# apollo4l register map
Vendor: Ambiq Micro; Series: Apollo; File version: 1.0
CPU: CM4 r1p0, little endian, MPU, FPU, I-cache, D-cache, VTOR, ITCM, DTCM, 3 interrupt priority bits, 0 interrupts
Registers are 32-bit, read-write, reset 0x0 unless marked. A register's access mark holds for its fields unless they carry their own. Offsets are from the block's base; [hi:lo] are bit positions; {n}, {i} and the like mark numbered series; 'fields as' and 'values as' point back to an identical list.

## CRYPTO (part 1 of 2) — Embedded security and cryptographic services
Base 0x400C0000
{0x0+4i} MEMORYMAP{i} (i=0..14) — This register maps the virtual register R{i} to a physical address in memory.
  [10:1] PHYSADDRMAP{i} — Contains the physical address in memory to map the R{i} register.
0x3C MEMORYMAP15 — This register maps the virtual register R15 to a physical address in memory.
  [10:1] PHYSADDRMAP15 — Contains the physical address in memory to map the R15 registero.
0x40 MEMORYMAP16 — This register maps the virtual register R16 to a physical address in memory.
  [10:1] PHYSADDRMAP16 — Contains the physical address in memory to map the R16 register.
0x44 MEMORYMAP17 — This register maps the virtual register R17 to a physical address in memory.
  [10:1] PHYSADDRMAP17 — Contains the physical address in memory to map the R17 registero.
0x48 MEMORYMAP18 — This register maps the virtual register R18 to a physical address in memory.
  [10:1] PHYSADDRMAP18 — Contains the physical address in memory to map the R18 register.
{0x0+4i} MEMORYMAP{i} (i=19..27) — This register maps the virtual register R{i} to a physical address in memory.
  [10:1] PHYSADDRMAP{i} — Contains the physical address in memory to map the R{i} register to.
{0x0+4i} MEMORYMAP{i} (i=28..31) — This register maps the virtual register R{i} to a physical address in memory.
  fields as MEMORYMAP0
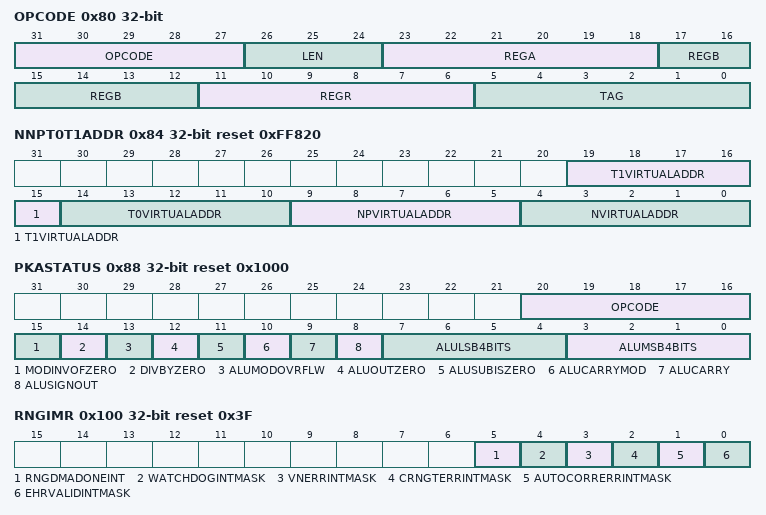
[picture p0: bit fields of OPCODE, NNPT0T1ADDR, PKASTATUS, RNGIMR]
0x80 OPCODE — This register holds the PKAs OPCODE.
  [31:27] OPCODE — Defines the PKA operation:
    4=ADD (Add,Inc opcode); 5=SUB (Sub,Dec,Neg opcode); 6=MODADD (ModAdd,ModInc opcode); 7=MODSUB (ModSub,ModDec,ModNeg opcode); 8=AND (AND,TST0,CLR0 opcode); 9=OR (OR,COPY,SET0 opcode); 10=XOR (XOR,FLIP0,INVERT,COMPARE opcode); 12=SHR0 (SHR0 opcode); 13=SHR1 (SHR1 opcode); 14=SHL0 (SHL0 opcode); 15=SHL1 (SHL1 opcode); 16=MULLOW (MulLow opcode); 17=MODMUL (ModMul opcode); 18=MODMULN (ModMulN opcode); 19=MODEXP (ModExp opcode); 20=DIVISION (Division opcode); 21=DIV (Div opcode); 22=MODDIV (ModDiv opcode); 0=TERMINATE (Terminate opcode)
  [26:24] LEN — The length of the operation. The value serves as a pointer to PKA length register, for example, if the value is 0, PKA_L0 holds the size of the operation.
  [23:18] REGA — Operand A virtual address 0-15.
  [17:12] REGB — Operand B virtual address 0-15.
  [11:6] REGR — Result register virtual address 0-15.
  [5:0] TAG — Holds the operations tag or the operand C virtual address.
0x84 NNPT0T1ADDR reset 0xFF820 — This register maps N_NP_T0_T1 to a virtual address.
  [19:15] T1VIRTUALADDR — Virtual address of temporary register number 1
  [14:10] T0VIRTUALADDR — Virtual address of temporary register number 0
  [9:5] NPVIRTUALADDR — Virtual address of register NP.
  [4:0] NVIRTUALADDR — Virtual address of register N.
0x88 PKASTATUS reset 0x1000 — This register holds the PKA pipe status.
  [20:16] OPCODE — Opcode of the last operation
  [15] MODINVOFZERO — Indicates the Modular inverse of zero.
  [14] DIVBYZERO — Indication if the division is done by zero.
  [13] ALUMODOVRFLW — Modular overflow flag.
  [12] ALUOUTZERO — Indicates if the result of ALU OUT is zero.
  [11] ALUSUBISZERO — Indicates the last subtraction operations sign .
  [10] ALUCARRYMOD — holds the carry of the last Modular operation.
  [9] ALUCARRY — Holds the carry of the last ALU operation.
  [8] ALUSIGNOUT — Indicates the last operations sign (MSB).
  [7:4] ALULSB4BITS — The least significant 4-bits of the operand updated in shift operation.
  [3:0] ALUMSB4BITS — The most significant 4-bits of the operand updated in shift operation.
0x8C PKASWRESET — Writing to this register triggers a software reset of the PKA.
  [0] PKASWRESET — The reset mechanism takes about four PKA clock cycles until the reset line is deasserted
{0x90+4i} PKAL{i} (i=0..7) — This register holds one of the optional size of the operation.
  [12:0] PKAL{i} — Size of the operation in bytes.
0xB0 PKAPIPERDY reset 0x1 — This register indicates whether the PKA pipe is ready to receive a new OPCODE.
  [0] PKAPIPERDY — Indication whether PKA pipe is ready for new OPCODE.
0xB4 PKADONE reset 0x1 — This register indicates whether PKA operation is completed.
  [0] PKADONE — Indicates if PKA operation is completed, and pipe is empty.
0xB8 PKAMONSELECT — This register defines which PKA FSM monitor is being output.
  [3:0] PKAMONSELECT — Defines which PKA FSM monitor is being output.
0xC4 PKAVERSION reset 0x16110215 — This register holds the pka version
  [31:0] PKAVERSION — This is the PKA version
0xD0 PKAMONREAD — The PKA monitor bus register.
  [31:0] PKAMONREAD — This is the PKA monitor bus register output
0xD4 PKASRAMADDR — first address given to PKA SRAM for write transactions.
  [31:0] PKASRAMADDR — PKA SRAM write starting address
0xD8 PKASRAMWDATA — Write data to PKA SRAM.
  [31:0] PKASRAMWDATA — 32 bit write to PKA SRAM: triggers the SRAM write DMA address automatically incremented
0xDC PKASRAMRDATA — Read data from PKA SRAM.
  [31:0] PKASRAMRDATA — 32 bit read from PKA SRAM: read - triggers the SRAM read DMA address automatically incremented
0xE0 PKASRAMWRCLR — Write buffer clean.
  [31:0] PKASRAMWRCLR — Clear the write buffer.
0xE4 PKASRAMRADDR — first address given to PKA SRAM for read transactions.
  [31:0] PKASRAMRADDR — PKA SRAM read starting address
0xF0 PKAWORDACCESS — This register holds the data written to PKA memory using the wop opcode.
  [31:0] PKAWORDACCESS — 32 bit read_write data.
0xF8 PKABUFFADDR — This register maps the virtual buffer registers to a physical address in memory.
  [11:0] PKABUFADDR — Contains the physical address in memory to map the buffer registers.
0x100 RNGIMR reset 0x3F — Interrupt masking register. Consists of {prng_imr trng_imr} bit[31-16] - PRNG_IMR bit[15-0] - TRNG_IMR(Ws - PRNG bit exists only if PRNG_EXISTS flag)
  [5] RNGDMADONEINT — 0x1 - masks the RNG DMA completion interrupt. No interrupt is generated.
  [4] WATCHDOGINTMASK — 0x1 - masks the watchdog interrupt. No interrupt is generated.
  [3] VNERRINTMASK — 0x1 - masks the Von-Neumann error interrupt. No interrupt is generated.
  [2] CRNGTERRINTMASK — 0x1 - masks the CRNGT error interrupt. No interrupt is generated.
  [1] AUTOCORRERRINTMASK — 0x1 - masks the autocorrelation interrupt. No interrupt is generated.
  [0] EHRVALIDINTMASK — 0x1 - masks the EHR interrupt. No interrupt is generated.
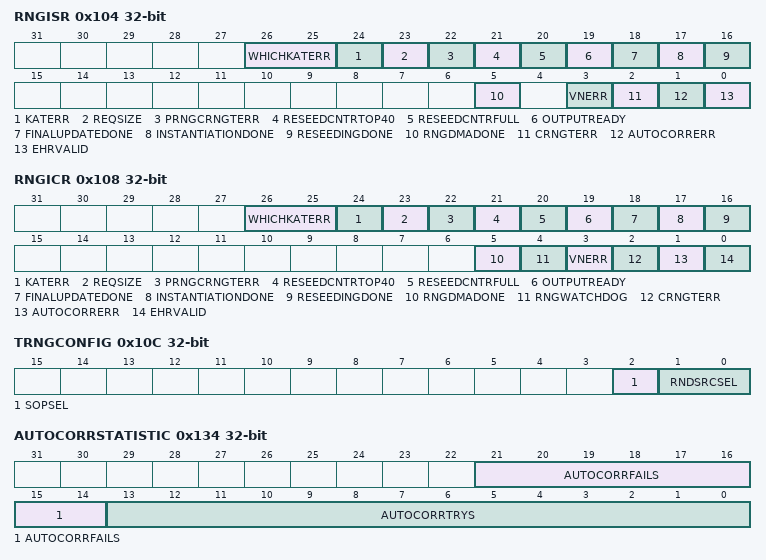
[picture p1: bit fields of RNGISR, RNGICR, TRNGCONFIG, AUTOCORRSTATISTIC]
0x104 RNGISR — Status register. If corresponding RNG_IMR bit is unmasked, an interrupt is generated.Consists of trng_isr and prng_isr bit[15-0] - TRNG bit[31-16] - PRNG
  [26:25] WHICHKATERR — When the KAT_ERR bit is set, these bits represent which Known Answer Test had failed:
    0=INSTANT_1 (first test of instantiation); 1=INSTANT_2 (second test of instantiation); 2=RESEED_1 (first test of reseeding); 3=RESEED_2 (second test of reseeding)
  [24] KATERR — 0x1 indicates that one of the KAT (Known Answer Tests) tests has failed. When set, the entire engine ceases to function.
  [23] REQSIZE — 0x1 indicates that the request size counter (which represents how many generations of random bits in the PRNG have been produced) has reached 2^12, thus requiring a working state update before generating new random numbers.
  [22] PRNGCRNGTERR — 0x1 indicates CRNGT in the PRNG test failed. Failure occurs when two consecutive results of AES are equal
  [21] RESEEDCNTRTOP40 — 0x1 indicates that the top 40 bits of the reseed counter are set (that is the reseed counter is larger than 2^48-2^8). This is a recommendation for running the reseed algorithm before the counter reaches its max value.
  [20] RESEEDCNTRFULL — 0x1 indicates that the reseed counter has reached 2^48, requiring to run the reseed algorithm before generating new random numbers.
  [19] OUTPUTREADY — 0x1 indicates that the result of PRNG is valid and ready to be read. The result can be read from the RNG_READOUT register.
  [18] FINALUPDATEDONE — 0x1 indicates completion of final update algorithm.
  [17] INSTANTIATIONDONE — 0x1 indicates completion of instantiation algorithm with no errors.
  [16] RESEEDINGDONE — 0x1 indicates completion of reseeding algorithm with no errors.
  [5] RNGDMADONE — 0x1 indicates RNG DMA to SRAM is completed.
  [3] VNERR — 0x1 indicates Von Neumann error. Error in von Neumann occurs if 32 consecutive collected bits are identical, ZERO, or ONE.
  [2] CRNGTERR — 0x1 indicates CRNGT in the TRNG test failed. Failure occurs when two consecutive blocks of 16 collected bits are equal.
  [1] AUTOCORRERR — 0x1 indicates Autocorrelation test failed four times in a row. When it set ,TRNG ceases to function until next reset.
  [0] EHRVALID — 0x1 indicates that 192 bits have been collected in the TRNG and are ready to be read.
0x108 RNGICR — Interrupt_status bit clear Register. Consists of trng_icr and prng_icr bit[15-0] - TRNG bit[31-16] - PRNG
  [26:25] WHICHKATERR — Cannot be cleared by SW! Only RNG reset clears this bit.
  [24] KATERR — Cannot be cleared by SW! Only RNG reset clears this bit.
  [23] REQSIZE — Writing value 0x1 - clears corresponding bit in RNGISR
  [22] PRNGCRNGTERR — Writing value 0x1 - clears corresponding bit in RNGISR
  [21] RESEEDCNTRTOP40 — Writing value 0x1 - clears corresponding bit in RNGISR
  [20] RESEEDCNTRFULL — Writing value 0x1 - clears corresponding bit in RNGISR
  [19] OUTPUTREADY — Writing value 0x1 - clears corresponding bit in RNGISR
  [18] FINALUPDATEDONE — Writing value 0x1 - clears corresponding bit in RNGISR
  [17] INSTANTIATIONDONE — Writing value 0x1 - clears corresponding bit in RNGISR
  [16] RESEEDINGDONE — Writing value 0x1 - clears corresponding bit in RNGISR
  [5] RNGDMADONE — Writing value 0x1 - clears corresponding bit in RNGISR
  [4] RNGWATCHDOG — Writing value 0x1 - clears corresponding bit in RNGISR
  [3] VNERR — Writing value 0x1 - clears corresponding bit in RNGISR
  [2] CRNGTERR — Writing value 0x1 - clears corresponding bit in RNGISR
  [1] AUTOCORRERR — Cannot be cleared by SW! Only RNG reset clears this bit.
  [0] EHRVALID — Writing value 0x1 - clears corresponding bit in RNGISR
0x10C TRNGCONFIG — This register handles TRNG configuration
  [2] SOPSEL — Secure Output Port selection:
    1=SOP_DATA_1 (sop_data port reflects TRNG output (EHR_DATA).); 0=SOP_DATA_2 (sop_data port reflects PRNG output (RNG_READOUT). Note: Secure output is used for direct connection of the RNG block outputs to an engine input key.)
  [1:0] RNDSRCSEL — Defines the length of the oscillator ring (= the number of inverters) out of four possible selections.
0x110 TRNGVALID — This register indicates that the TRNG data is valid.
  [0] EHRVALID — 0x1 indicates that collection of bits in the TRNG is completed, and data can be read from the EHR_DATA register.
{0x114+4i} EHRDATA{i} (i=0..5) — This register contains the data collected in the TRNG[{32i+31}_{32i}]. Note: can only be set while in debug mode (rng_debug_enable input is set).
  [31:0] EHRDATA — Contains the data collected in the TRNG[{32i+31}_{32i}]. Note: can only be set while in debug mode (rng_debug_enable input is set).
0x12C RNDSOURCEENABLE — This register holds the enable signal for the random source.
  [0] RNDSRCEN — Enable signal for the random source.
0x130 SAMPLECNT1 reset 0xFFFF — Counts clocks between sampling of random bit.
  [31:0] SAMPLECNTR1 — Sets the number of rng_clk cycles between two consecutive ring oscillator samples. Note: If the Von-Neumann is bypassed, the minimum value for sample counter must not be less than decimal seventeen.
0x134 AUTOCORRSTATISTIC — Statistics about autocorrelation test activations.
  [21:14] AUTOCORRFAILS — Count each time an autocorrelation test fails. Any write to the register resets the counter. Stops collecting statistics if one of the counters has reached the limit.
  [13:0] AUTOCORRTRYS — Count each time an autocorrelation test starts. Any write to the register resets the counter. Stops collecting statistics if one of the counters has reached the limit.
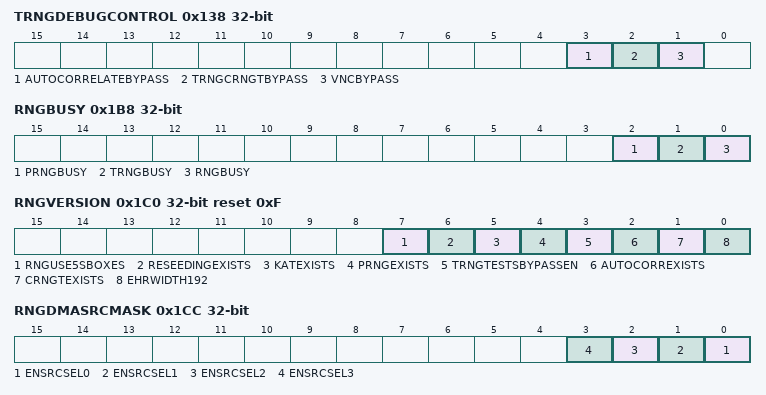
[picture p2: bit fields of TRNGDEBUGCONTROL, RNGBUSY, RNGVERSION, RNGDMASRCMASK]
0x138 TRNGDEBUGCONTROL — This register is used to debug the TRNG
  [3] AUTOCORRELATEBYPASS — When this bit is set, the autocorrelation test in the TRNG module is bypassed. Note: Can only be set while in debug mode. If TRNG_TESTS_BYPASS_EN HW flag is defined, this bit can be set while not in debug mode.
  [2] TRNGCRNGTBYPASS — When this bit is set, the CRNGT test in the TRNG is bypassed. Note: Can only be set while in debug mode. If TRNG_TESTS_BYPASS_EN HW flag is defined, this bit can be set while not in debug mode.
  [1] VNCBYPASS — When this bit is set, the Von-Neumann balancer is bypassed (including the 32 consecutive bits test). Note: Can only be set while in debug mode. If TRNG_TESTS_BYPASS_EN HW flag is defined, this bit can be set while not in debug mode.
0x140 RNGSWRESET — Generate SW reset solely to RNG block.
  [0] RNGSWRESET — Any value written (0x0 or 0x1) causes a reset cycle to the TRNG block.
0x1B4 RNGDEBUGENINPUT — Defines the RNG in debug mode
  [0] RNGDEBUGEN — Reflects the rng_debug_enable input port
0x1B8 RNGBUSY — RNG busy indication
  [2] PRNGBUSY — Reflects prng_busy.
  [1] TRNGBUSY — Reflects trng_busy.
  [0] RNGBUSY — Reflects rng_busy output port which Consists of trng_busy and prng_busy.
0x1BC RSTBITSCOUNTER — Resets the counter of collected bits in the TRNG
  [0] RSTBITSCOUNTER — Writing any value to this address resets the bits counter and trng valid registers.
0x1C0 RNGVERSION reset 0xF — This register holds the RNG version
  [7] RNGUSE5SBOXES — RNG use 5 (or 20) SBOX AES
    0=20_SBOX_AES; 1=5_SBOX_AES
  [6] RESEEDINGEXISTS
    1=EXISTS; 0=NORESEED (Reseed does not exists)
  [5] KATEXISTS
    0=NO_EXIST (does not exist); 1=EXISTS
  [4] PRNGEXISTS
    0=NO_EXIST (does not exist); 1=EXISTS
  [3] TRNGTESTSBYPASSEN — TRNG tests bypass enable.
    0=TRNG_NE (trng tests bypass not enabled); 1=TRNG_E (trng tests bypass enabled)
  [2] AUTOCORREXISTS — Auto correct exists.
    0=NO_EXIST (does not exist); 1=EXISTS
  [1] CRNGTEXISTS
    0=NO_EXIST (does not exist); 1=EXISTS
  [0] EHRWIDTH192 — EHR width selection.
    0=128_EHR (128 bit EHR); 1=192_EHR (192 bit EHR)
0x1C4 RNGCLKENABLE — Writing to this register enables_disables the RNG clock.
  [0] EN — Writing value 0x1 enables RNG clock.
0x1C8 RNGDMAENABLE — Writing to this register enables_disables the RNG DMA.
  [0] EN — Writing value 0x1 enables RNG DMA to SRAM. The Value is cleared when DMA completes its operation.
0x1CC RNGDMASRCMASK — This register defines which ring-oscillator length should be used when using the RNG DMA.
  [n] ENSRCSEL{n} (n=0..3) — Writing value 0x1 enables SRC_SEL {n}.
0x1D0 RNGDMASRAMADDR — This register defines the start address of the DMA for the TRNG data.
  [10:0] RNGSRAMDMAADDR — Defines the start address of the DMA for the TRNG data.
0x1D8 RNGWATCHDOGVAL — This register defines the number of 192-bits samples that the DMA collects per RNG configuration.bitfield 7:0 RNG_SAMPLES_NUM rw 0x0 Defines the number of 192-bits samples that the DMA collects per RNG configuration.bitfield 31:8 RESERVED rw 0x0 ReservedThis register defines the maximum number of clock cycles per TRNG collection of 192 samples. If the number of cycles for a collection exceeds this threshold, TRNG signals an interrupt.
  [31:0] RNGWATCHDOGVAL — Defines the maximum number of clock cycles per TRNG collection of 192 samples. If the number of cycles for a collection exceeds this threshold, TRNG signals an interrupt.
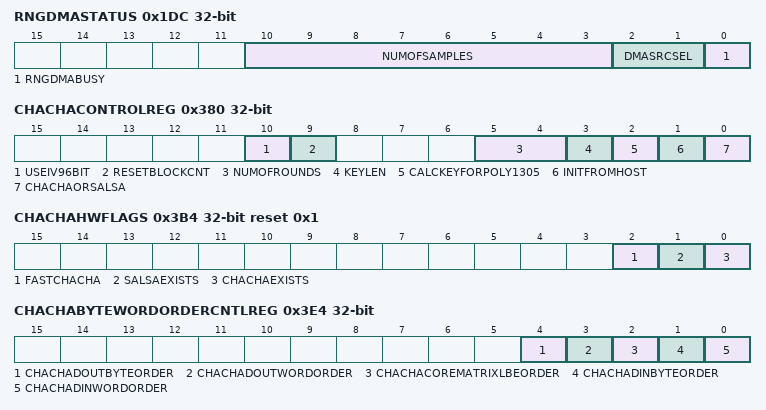
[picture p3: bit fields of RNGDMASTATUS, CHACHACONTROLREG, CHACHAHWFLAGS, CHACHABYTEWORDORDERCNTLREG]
0x1DC RNGDMASTATUS — This register holds the RNG DMA status.
  [10:3] NUMOFSAMPLES — Number of samples already collected in the current ring oscillator chain length.
  [2:1] DMASRCSEL — The active ring oscillator length using by DMA
  [0] RNGDMABUSY — Indicates whether DMA is busy.
0x380 CHACHACONTROLREG — CHACHA general configuration.
  [10] USEIV96BIT — If use 96bit IV
  [9] RESETBLOCKCNT — For new message
  [5:4] NUMOFROUNDS — The core of ChaCha is a hash function which based on rotation operations. The hash function consist in application of 20 rounds (default value). In additional, ChaCha have two variants (they work exactly as the original algorithm): ChaCha20_8 and ChaCha20_12 (using 8 and 12 rounds).
    0=20_ROUNDS; 1=12_ROUNDS; 2=8_ROUNDS; 3=N_A (Not applicable)
  [3] KEYLEN — For All Core:
    0=256_BIT; 1=128_BIT
  [2] CALCKEYFORPOLY1305 — Only if ChaCha core:
    0=DISABLE; 1=ENABLE
  [1] INITFROMHOST — Start init for new Message:
    0=DISABLE; 1=ENABLE
  [0] CHACHAORSALSA — Core:
    0=CHACHA (ChaCha mode,); 1=SALSA (Salsa mode.)
0x384 CHACHAVERSION reset 0x1
0x388 CHACHAKEY0 — bits 255:224 of CHACHA Key
0x38C CHACHAKEY1 — bits 223:192 of CHACHA Key
0x390 CHACHAKEY2 — bits 191:160 of CHACHA Key
  [31:0] CHACHAKEY2 — bits191:160 of CHACHA Key
0x394 CHACHAKEY3 — bits159:128 of CHACHA Key
  [31:0] CHACHAKEY3 — bits 159:128 of CHACHA Key
0x398 CHACHAKEY4 — bits 127:96 of CHACHA Key
0x39C CHACHAKEY5 — bits 95:64 of CHACHA Key
0x3A0 CHACHAKEY6 — bits 63:32 of CHACHA Key
0x3A4 CHACHAKEY7 — bits 31:0 of CHACHA Key
0x3A8 CHACHAIV0 — bits 31:0 of CHACHA_IV0 register
0x3AC CHACHAIV1 — bits 31:0 of CHACHA_IV1 register
0x3B0 CHACHABUSY — This register is set when the CHACHA_SALSA core is active
  [0] CHACHABUSY — CHACHA_BUSY Register. This register is set when the CHACHA_SALSA core is active.
0x3B4 CHACHAHWFLAGS reset 0x1 — This register holds the pre-synthesis HW flag configuration of the CHACHA_SALSA engine
  [all] fields
    0=DISABLE; 1=ENABLE
  [2] FASTCHACHA — If this flag is set, the next matrix calculated when the current one is written to data output path (same flag for Salsa core):
  [1] SALSAEXISTS — If this flag is set, the Salsa_ChaCha engine include Salsa implementation:
  [0] CHACHAEXISTS — If this flag is set, the Salsa_ChaCha engine include ChaCha implementation:
0x3B8 CHACHABLOCKCNTLSB — The two first words (n) in the last row of the cipher matrix are the block counter. At the end of each block (512b), the block_cnt for the next block is written by HW to the block_cnt_lsb and block_cnt_msb registers. Need reset block counter , if start new message.
  [31:0] CHACHABLOCKCNTLSB — bits 31:0 of CHACHA_BLOCK_CNT_LSB register.
0x3BC CHACHABLOCKCNTMSB — The two first words (n) in the last row of the cipher matrix are the block counter. At the end of each block (512b), the block_cnt for the next block is written by HW to the block_cnt_lsb and block_cnt_msb registers. Need reset block counter , if start new message.
  [31:0] CHACHABLOCKCNTMSB — bits 31:0 of CHACHA_BLOCK_CNT_MSB register.
0x3C0 CHACHASWRESET — Resets CHACHA_SALSA engine.
  [0] CHACHSWRESET — Writing to this address resets the only FSM of CHACHA engine. The reset takes 4 CORE_CLK cycles.
0x3C4 CHACHAFORPOLYKEY0 — bits 255:224 of CHACHA_FOR_POLY_KEY
0x3C8 CHACHAFORPOLYKEY1 — bits 223:192 of CHACHA_FOR_POLY_KEY
0x3CC CHACHAFORPOLYKEY2 — bits191:160 of CHACHA_FOR_POLY_KEY
0x3D0 CHACHAFORPOLYKEY3 — bits159:128 of CHACHA_FOR_POLY_KEY
  [31:0] CHACHAFORPOLYKEY3 — bits 159:128 of CHACHA_FOR_POLY_KEY
0x3D4 CHACHAFORPOLYKEY4 — bits 127:96 of CHACHA_FOR_POLY_KEY
0x3D8 CHACHAFORPOLYKEY5 — bits 95:64 of CHACHA_FOR_POLY_KEY
0x3DC CHACHAFORPOLYKEY6 — bits 63:32 of CHACHA_FOR_POLY_KEY
0x3E0 CHACHAFORPOLYKEY7 — bits 31:0 of CHACHA_FOR_POLY_KEY
0x3E4 CHACHABYTEWORDORDERCNTLREG — CHACHA_SALSA DATA ORDER configuration.
  [4] CHACHADOUTBYTEORDER — Change the byte order of the output data.
    0=DISABLE; 1=ENABLE (enable. (reverse each byte in each word output (b0->b3, b1->b2, b2->b1,b3->b0)))
  [3] CHACHADOUTWORDORDER — Change the words order of the output data.
    0=DISABLE; 1=ENABLE (enable. (reverse each word in 128 bit output ( w0->w3, w1->w2, w2->w1,w3-w0)))
  [2] CHACHACOREMATRIXLBEORDER — Change the quarter of a matrix order in core
    0=DISABLE; 1=ENABLE (enable. (reverse each quarter of a matrix (m[0-127]->m[384-511], m[128-255]->m[256-383], m[256-383]->m[128-255], m[384-511]->m[0-127])))
  [1] CHACHADINBYTEORDER — Change the byte order of the input data.
    0=DISABLE; 1=ENABLE (enable. (reverse each byte in each word input (b0->b3, b1->b2, b2->b1,b3->b0)))
  [0] CHACHADINWORDORDER — Change the words order of the input data.
    0=DISABLE; 1=ENABLE (enable. (reverse each word in 128 bit input ( w0->w3, w1->w2, w2->w1,w3-w0)))
0x3E8 CHACHADEBUGREG — This register is used to debug the CHACHA engine
  [1:0] CHACHADEBUGFSMSTATE
    0=IDLE_STATE (The idle state.); 1=INIT_STATE (The init state.)
{0x400+4i} AESKEY{i:02} (i=0..3) — bits {32i+31}:{32i} of AES Key0 (used as the AES key in non-tunneling operations, and as the first tunnel stage key in tunneling operations).
  [31:0] AESKEY{i:02} — bits {32i+31}:{32i} of AES Key0.
0x410 AESKEY04 — bits 159:128 of AES Key0 (used as the AES key in non-tunneling operations, and as the first tunnel stage key in tunneling operations).
  [31:0] AESKEY04 — bits 159:128 of AES Key0 .
{0x400+4i} AESKEY{i:02} (i=5..7) — bits {32i+31}:{32i} of AES Key0 (used as the AES key in non-tunneling operations, and as the first tunnel stage key in tunneling operations).
  [31:0] AESKEY{i:02} — bits {32i+31}:{32i} of AES Key0.
{0x3F8+4i} AESKEY{i} (i=10..17) — bits {32i-289}:{32i-320} of AES Key1 (used as the second AES tunnel stage key in tunneling operations).
  [31:0] AESKEY{i} — bits {32i-289}:{32i-320} of AES Key1.
0x440 AESIV00 — bits 31:0 of AES_IV0 register. AES IV0 is used as the AES IV (Initialization Value) register in non-tunneling operations,and as the first tunnel stage IV register in tunneling operations.The IV register should be loaded according to the AES mode:in AES CBC_CBC-MAC - the AES IV register should be loaded with the IV (initialization vector).in XTS-AES - the AES IV register should be loaded with the T value (unless the HW T calculation mode is active, in which the T value is calculated by the HW).
  [31:0] AESIV00 — bits 31:0 of AES_IV0 register.
{0x440+4i} AESIV{i:02} (i=1..3) — bits {32i+31}:{32i} of AES_IV0 128b register.For the description of AES_IV0, see the AES_IV_0_0 register description
  [31:0] AESIV{i:02} — bits {32i+31}:{32i} of AES_IV0 register.
0x450 AESIV10 — bits 31:0 of AES_IV1 128b register.AES IV1 is used as the AES IV (Initialization Value) register as the second tunnel stage IV register in tunneling operations.The IV register should be loaded according to the AES mode:in AES CBC_CBC-MAC - the AES IV register should be loaded with the IV (initialization vector).in XTS-AES - the AES IV register should be loaded with the T value (unless the HW T calculation mode is active, in which the T value is calculated by the HW.
  [31:0] AESIV10 — bits 31:0 of AES_IV1 register.
{0x428+4i} AESIV{i} (i=11..13) — bits {32i-289}:{32i-320} of AES_IV1 128b register.For the description of AES_IV1, see the AES_IV_1_0 register description
  [31:0] AESIV{i} — bits {32i-289}:{32i-320} of AES_IV1 register.
0x460 AESCTR00 — bits 31:0 of AES_CTR0 128b register.AES CTR0 is used as the AES CTR (counter) register in non-tunneling operations, and as the first tunnel stage CTR register in tunneling operations.The CTR register should be loaded according to the AES mode:in AES CTR_GCTR - the AES CTR register should be loaded with the counter value.in XTS-AES - the AES CTR register should be loaded with the i value (in order to calculate the T value from it, if HW T calculation is supported).
  [31:0] AESCTR00 — bits 31:0 of AES_CTR0 register.
{0x460+4i} AESCTR{i:02} (i=1..3) — bits {32i+31}:{32i} of AES_CTR0 128b register.For the description of AES_CTR0, see the AES_CTR_0_0 register description.
  [31:0] AESCTR{i:02} — bits {32i+31}:{32i} of AES_CTR0 register.
0x470 AESBUSY — This register is set when the AES core is active
  [0] AESBUSY — AES_BUSY register. This register is set when the AES core is active
0x478 AESSK — writing to this address causes sampling of the HW key to the AES_KEY0 register
  [0] AESSK
0x47C AESCMACINIT — Writing to this address triggers the AES engine generating of K1 and K2 for AES CMAC operations. Note: This is a special register, affected by internal logic. Test result of this register is NA.
  [0] AESCMACINIT — Writing to this address starts the generating of K1 and K2 for AES CMAC operations
0x4B4 AESSK1 — writing to this address causes sampling of the HW key to the AES_KEY1 register
  [0] AESSK1
0x4BC AESREMAININGBYTES — This register should be set with the amount of remaining bytes until the end of the current AES operation. The AES engine counts down from this value to determine the last _ one before last blocks in AES CMAC, XTS AES and AES CCM.
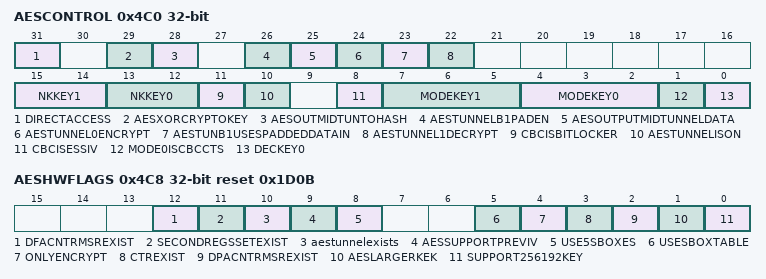
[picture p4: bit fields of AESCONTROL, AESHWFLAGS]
0x4C0 AESCONTROL — This register holds the configuration of the AES engine. Note: This is a special register, affected by internal logic. Test result of this register is NA.
  [31] DIRECTACCESS — Using direct access and not the din-dout interface
  [29] AESXORCRYPTOKEY — This field determines the value that is written to AES_KEY0, when AES_SK is kicked:
    0=CRYPTOKEY (The value that is written to AES_KEY0 is the value of the HW cryptokey, as is.); 1=CRYPTOKEY_XOR (The value that is written to AES_KEY0 is the value of the HW cryptokey xored with the current value of AES_KEY0.)
  [28] AESOUTMIDTUNTOHASH — This field determines for AES-TO-HASH-AND-DOUT tunneling operations, whether the AES outputs to the HASH the result of the first or the second tunneling stage:
    0=HASH_2 (The AES engine writes to the hash the result of the second tunnel stage.); 1=HASH_1 (The AES engine writes to the hash the result of the first tunnel stage.)
  [26] AESTUNNELB1PADEN — This field determines whether the input data to the second tunnel stage is padded with zeroes (according to the remaining_bytes value) or not:
    0=DATA_NO_PAD (The data input to the second tunnel block is not padded with zeros.); 1=DATA_IS_PAD (The data input to the second tunnel block is padded with zeros.)
  [25] AESOUTPUTMIDTUNNELDATA — This fields determines whether the AES output is the result of the first or second tunneling stage:
    0=ENGINE_RSLT_2 (The AES engine outputs the result of the second tunnel stage (standard tunneling).); 1=ENGINE_RSLT_1 (The AES engine outputs the result of the first tunnel stage.)
  [24] AESTUNNEL0ENCRYPT — This field determines whether the first tunnel stage performs encrypt or decrypt operation :
    0=TUNNEL_1_D (the first tunnel stage performs decrypt operations.); 1=TUNNEL_1_E (the first tunnel stage performs encrypt operations.)
  [23] AESTUNB1USESPADDEDDATAIN — This field determines, for tunneling operations, the data that is fed to the second tunneling stage:
    0=BLOCK_1 (the output of the first block (standard tunneling operation).); 1=AFTER_PAD (data_in after padding rather than the output of the first block.)
  [22] AESTUNNEL1DECRYPT — This field determines whether the second tunnel stage performs encrypt or decrypt operation :
    0=TUNNEL_2_E (the second tunnel stage performs encrypt operations.); 1=TUNNEL_2_D (the second tunnel stage performs decrypt operations.)
  [15:14] NKKEY1 — This field determines the AES key length of the second stage operation in tunneling operations:
    0=128_BITS_KEY; 1=192_BITS_KEY; 2=256_BITS_KEY; 3=N_A (Not applicable)
  [13:12] NKKEY0 — This field determines the AES Key length in non tunneling operations, and the AES key length of the first stage in tunneling operations:
    values as NKKEY1
  [11] CBCISBITLOCKER — If MODE_KEY0 is set to 3b001 (CBC), and this field is set - the mode isBITLOCKER.
  [10] AESTUNNELISON — This field determines whether the AES performs dual-tunnel operations or standard non-tunneling operations:
    0=STD_NONTUNNEL (standard non-tunneling operations); 1=TUNNEL (tunneling operations.)
  [8] CBCISESSIV — If MODE_KEY0 is set to 3b001 (CBC), and this field is set - the mode is CBC with ESSIV.
  [7:5] MODEKEY1 — This field determines the AES mode of the second stage operation in tunneling operations:
    0=ECB (ECB modekey1); 1=CBC (CBC modekey1); 2=CTR (CTR modekey1); 3=CBC_MAC (CBC MAC modekey1); 4=XEX_XTS (XEX_XTS modekey1); 5=XCBC_MAC (XCBC MAC modekey1); 6=OFB (OFB modekey1); 7=CMAC (CMAC modekey1)
  [4:2] MODEKEY0 — This field determines the AES mode in non tunneling operations, and the AES mode of the first stage in tunneling operations:
    0=ECB (ECB modekey0); 1=CBC (CBC modekey0); 2=CTR (CTR modekey0); 3=CBCMAC (CBCMAC modekey0); 4=XEX_XTS (XEX XTS modekey0); 5=XCBC_MAC (XCBC MAC modekey0); 6=OFB (OFB modekey0); 7=CMAC (CMAC modekey0)
  [1] MODE0ISCBCCTS — If MODE_KEY0 is set to 3b001 (CBC), and this field is set - the mode is CBC-CTS. In addition, If MODE_KEY0 is set to 3b010 (CTR), and this field is set - the mode is GCTR.
  [0] DECKEY0 — This field determines whether the AES performs Decrypt_Encrypt operations, in non-tunneling operations:
    0=ENCRYPT; 1=DECRYPT
0x4C8 AESHWFLAGS reset 0x1D0B — This register holds the pre-synthesis HW flag configuration of the AES engine
  [12] DFACNTRMSREXIST — the DFA_CNTRMSR_EXIST flag
  [11] SECONDREGSSETEXIST — the SECOND_REGS_SET_EXIST flag
  [10] aestunnelexists — the aes_tunnel_exists flag
  [9] AESSUPPORTPREVIV — the AES_SUPPORT_PREV_IV flag
  [8] USE5SBOXES — the USE_5_SBOXES flag
  [5] USESBOXTABLE — the USE_SBOX_TABLE flag
  [4] ONLYENCRYPT — the ONLY_ENCRYPT flag
  [3] CTREXIST — the CTR_EXIST flag
  [2] DPACNTRMSREXIST — the DPA_CNTRMSR_EXIST flag
  [1] AESLARGERKEK — the AES_LARGE_RKEK flag
  [0] SUPPORT256192KEY — the SUPPORT_256_192_KEY flag
0x4D8 AESCTRNOINCREMENT — This register enables the AES CTR no increment mode (in which the counter mode is not incremented between 2 blocks)
  [0] AESCTRNOINCREMENT — This field enables the AES CTR 'no increment' mode (in which the counter mode is not incremented between 2 blocks)
0x4F0 AESDFAISON — This register disable_enable the AES dfa. Note: This is a special register, affected by internal logic. Test result of this register is NA.
  [0] AESDFAISON — writing to this register turns the DFA counter-measures on. this register exists only if DFA countermeasures are supported
0x4F8 AESDFAERRSTATUS — dfa error status register.
  [0] AESDFAERRSTATUS — after a DFA violation this register is set and the AES block is disabled) until the next reset. this register only exists if DFA countermeasures is are supported
0x524 AESCMACSIZE0KICK — writing to this address triggers the AES engine to perform a CMAC operation with size 0. The CMAC result can be read from the AES_IV0 register.
  [0] AESCMACSIZE0KICK
{0x640+4i} HASHH{i} (i=0..3) — H{i} data. can only be written in the following HASH_CONTROL modes: MD5 SHA1 SHA224 SHA256 SHA384 SHA512
  [31:0] HASHH{i} — 1) Write initial Hash value.
0x650 HASHH4 — H4 data. can only be written in the following HASH_CONTROL modes: SHA1 SHA224 SHA256 SHA384 SHA512
  [31:0] HASHH4 — 1) Write initial Hash value.
